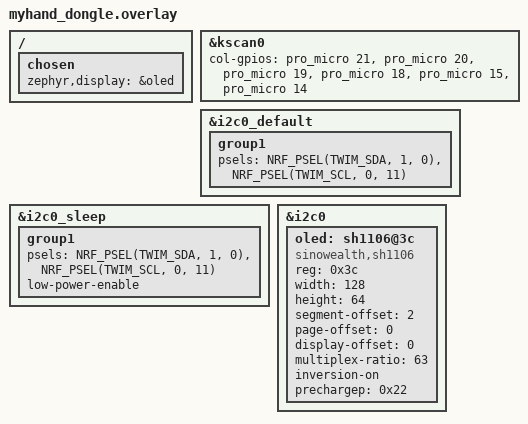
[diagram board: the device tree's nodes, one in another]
/*
 * Copyright (c) 2020 Pete Johanson
 *
 * SPDX-License-Identifier: MIT
 */

#include "myhand.dtsi"

/{
    chosen {
        zephyr,display = &oled;
    };
};

&kscan0 {
    col-gpios
        = <&pro_micro 21 GPIO_ACTIVE_HIGH>
        , <&pro_micro 20 GPIO_ACTIVE_HIGH>
        , <&pro_micro 19 GPIO_ACTIVE_HIGH>
        , <&pro_micro 18 GPIO_ACTIVE_HIGH>
        , <&pro_micro 15 GPIO_ACTIVE_HIGH>
        , <&pro_micro 14 GPIO_ACTIVE_HIGH>
        ;
};

&i2c0_default {
    group1 {
        psels = <NRF_PSEL(TWIM_SDA, 1, 0)>,
            <NRF_PSEL(TWIM_SCL, 0, 11)>;
    };
};

&i2c0_sleep {
    group1 {
        psels = <NRF_PSEL(TWIM_SDA, 1, 0)>,
            <NRF_PSEL(TWIM_SCL, 0, 11)>;
        low-power-enable;
    };
};

&i2c0 {
    status = "okay";
 
    oled: sh1106@3c {
        compatible = "sinowealth,sh1106";
        reg = <0x3c>;
        width = <128>;
        height = <64>;
        segment-offset = <2>;
        page-offset = <0>;
        display-offset = <0>;
        multiplex-ratio = <63>;
        inversion-on;
        prechargep = <0x22>;
    };
}; 

